# ATSAMC21G17A register map
Vendor: Microchip Technology; Series: SAMC21; File version: 0
CPU: CM0+ r0p0, selectable endian, MPU, no FPU, 2 interrupt priority bits
Registers are 32-bit, read-write, reset 0x0 unless marked. A register's access mark holds for its fields unless they carry their own. Offsets are from the block's base; [hi:lo] are bit positions; {n}, {i} and the like mark numbered series; 'fields as' and 'values as' point back to an identical list.

## TSENS — Temperature Sensor
Base 0x40003000; register names take the prefix TSENS_
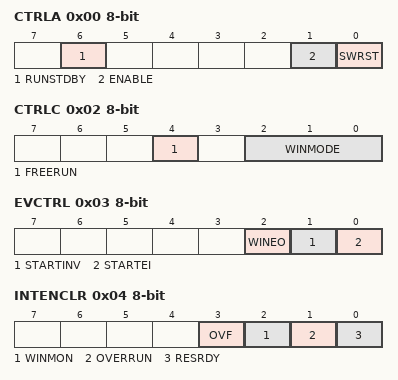
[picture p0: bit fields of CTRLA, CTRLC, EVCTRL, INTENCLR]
0x00 CTRLA 8-bit — Control A Register
  [6] RUNSTDBY — Run in Standby
  [1] ENABLE
  [0] SWRST — Software Reset
0x01 CTRLB 8-bit wo — Control B Register
  [0] START — Start Measurement
0x02 CTRLC 8-bit — Control C Register
  [4] FREERUN — Free Running Measurement
  [2:0] WINMODE — Window Monitor Mode
    0=DISABLE (No window mode (default)); 1=ABOVE (VALUE greater than WINLT); 2=BELOW (VALUE less than WINUT); 3=INSIDE (VALUE greater than WINLT and VALUE less than WINUT); 4=OUTSIDE (VALUE less than WINLT or VALUE greater than WINUT); 5=HYST_ABOVE (VALUE greater than WINUT with hysteresis to WINLT); 6=HYST_BELOW (VALUE less than WINLST with hysteresis to WINUT)
0x03 EVCTRL 8-bit — Event Control Register
  [2] WINEO — Window Monitor Event Out
  [1] STARTINV — Start Conversion Event Invert Enable
  [0] STARTEI — Start Conversion Event Input Enable
0x04 INTENCLR 8-bit — Interrupt Enable Clear Register
  [3] OVF — Overflow Interrupt Enable
  [2] WINMON — Window Monitor Interrupt Enable
  [1] OVERRUN — Overrun Interrupt Enable
  [0] RESRDY — Result Ready Interrupt Enable
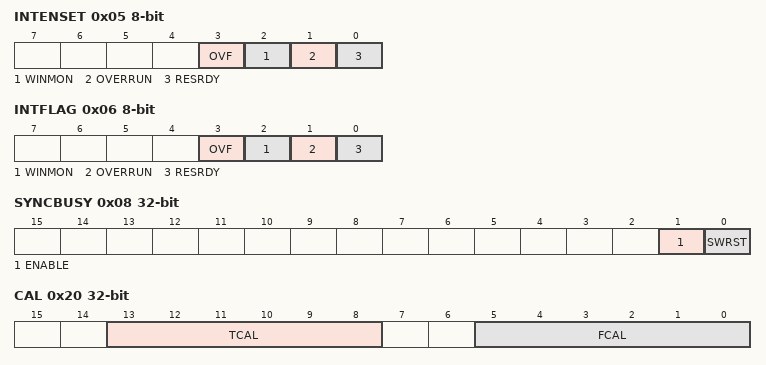
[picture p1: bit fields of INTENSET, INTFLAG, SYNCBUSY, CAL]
0x05 INTENSET 8-bit — Interrupt Enable Set Register
  fields as INTENCLR
0x06 INTFLAG 8-bit — Interrupt Flag Status and Clear Register
  [3] OVF write-1-clears — Overflow
  [2] WINMON write-1-clears — Window Monitor
  [1] OVERRUN write-1-clears
  [0] RESRDY write-1-clears — Result Ready
0x07 STATUS 8-bit ro
  [0] OVF — Result Overflow
0x08 SYNCBUSY ro — Synchronization Busy Register
  [1] ENABLE — Enable Busy
  [0] SWRST — Software Reset Busy
0x0C VALUE ro
  [23:0] VALUE — Measurement Value
0x10 WINLT — Window Monitor Lower Threshold Register
  [23:0] WINLT — Window Lower Threshold
0x14 WINUT — Window Monitor Upper Threshold Register
  [23:0] WINUT — Window Upper Threshold
0x18 GAIN
  [23:0] GAIN — Time Amplifier Gain
0x1C OFFSET
  [23:0] OFFSETC — Offset Correction
0x20 CAL — Calibration Register
  [13:8] TCAL — Temperature Calibration
  [5:0] FCAL — Frequency Calibration
0x24 DBGCTRL 8-bit — Debug Control Register
  [0] DBGRUN — Debug Run

## WDT — Watchdog Timer
Base 0x40002000; register names take the prefix WDT_
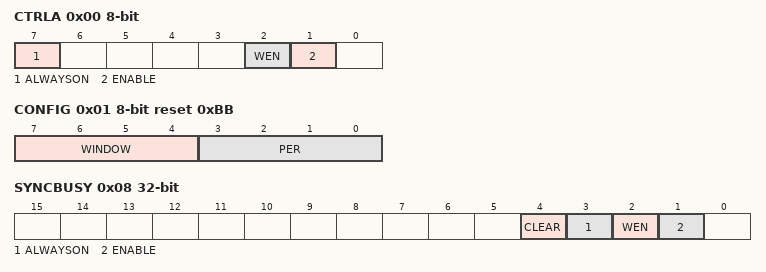
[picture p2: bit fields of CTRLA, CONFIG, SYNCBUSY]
0x00 CTRLA 8-bit — Control
  [7] ALWAYSON
  [2] WEN — Watchdog Timer Window Mode Enable
  [1] ENABLE
0x01 CONFIG 8-bit reset 0xBB — Configuration
  [7:4] WINDOW — Window Mode Time-Out Period
    0=CYC8 (8 clock cycles); 1=CYC16 (16 clock cycles); 2=CYC32 (32 clock cycles); 3=CYC64 (64 clock cycles); 4=CYC128 (128 clock cycles); 5=CYC256 (256 clock cycles); 6=CYC512 (512 clock cycles); 7=CYC1024 (1024 clock cycles); 8=CYC2048 (2048 clock cycles); 9=CYC4096 (4096 clock cycles); 10=CYC8192 (8192 clock cycles); 11=CYC16384 (16384 clock cycles)
  [3:0] PER — Time-Out Period
    values as WINDOW
0x02 EWCTRL 8-bit reset 0xB — Early Warning Interrupt Control
  [3:0] EWOFFSET — Early Warning Interrupt Time Offset
    values as CONFIG.WINDOW
0x04 INTENCLR 8-bit — Interrupt Enable Clear
  [0] EW — Early Warning Interrupt Enable
0x05 INTENSET 8-bit — Interrupt Enable Set
  [0] EW — Early Warning Interrupt Enable
0x06 INTFLAG 8-bit — Interrupt Flag Status and Clear
  [0] EW write-1-clears — Early Warning
0x08 SYNCBUSY ro — Synchronization Busy
  [4] CLEAR — Clear Busy
  [3] ALWAYSON — Always-On Busy
  [2] WEN — Window Enable Busy
  [1] ENABLE — Enable Busy
0x0C CLEAR 8-bit wo
  [7:0] CLEAR — Watchdog Clear
    165=KEY (Clear Key)

## MPU — Memory Protection Unit
Base 0xE000ED90; register names take the prefix MPU_
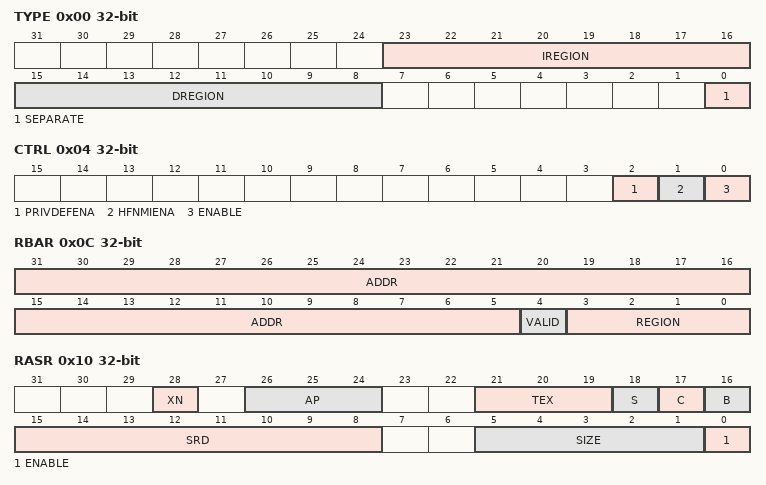
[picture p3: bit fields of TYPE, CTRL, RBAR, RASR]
0x00 TYPE ro — MPU Type Register
  [23:16] IREGION — Number of Instruction Regions
  [15:8] DREGION — Number of Data Regions
  [0] SEPARATE — Separate instruction and Data Memory MapsRegions
0x04 CTRL — MPU Control Register
  [2] PRIVDEFENA — Enables privileged software access to default memory map
  [1] HFNMIENA — Enable Hard Fault and NMI handlers
  [0] ENABLE — MPU Enable
0x08 RNR — MPU Region Number Register
  [7:0] REGION — Region referenced by RBAR and RASR
0x0C RBAR — MPU Region Base Address Register
  [31:5] ADDR — Region base address
  [4] VALID — Region number valid
  [3:0] REGION — Region number
0x10 RASR — MPU Region Attribute and Size Register
  [28] XN — Execute Never Attribute
  [26:24] AP — Access Permission
  [21:19] TEX — TEX bit
  [18] S — Shareable bit
  [17] C — Cacheable bit
  [16] B — Bufferable bit
  [15:8] SRD — Sub-region disable
  [5:1] SIZE — Region Size
  [0] ENABLE — Region Enable

## NVIC — Nested Vectored Interrupt Controller
Base 0xE000E100; register names take the prefix NVIC_
0x00 ISER — Interrupt Set Enable Register
  [30:0] SETENA — Interrupt set enable bits
0x80 ICER — Interrupt Clear Enable Register
  [30:0] CLRENA — Interrupt clear-enable bits
0x100 ISPR — Interrupt Set Pending Register
  [30:0] SETPEND — Interrupt set-pending bits
0x180 ICPR — Interrupt Clear Pending Register
  [30:0] CLRPEND — Interrupt clear-pending bits
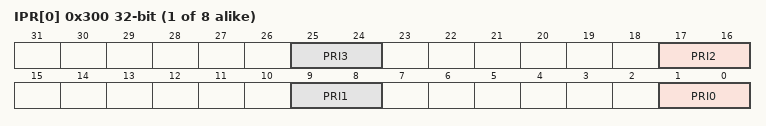
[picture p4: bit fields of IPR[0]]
{0x300+4i} IPR[{i}] (i=0..7) — Interrupt Priority Register n
  [8n+1:8n] PRI{n} (n=0..3) — Priority of interrupt n
